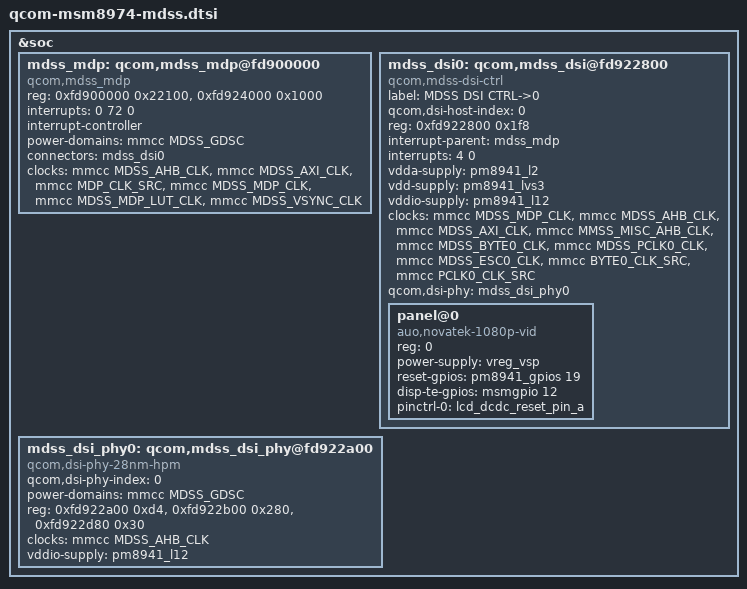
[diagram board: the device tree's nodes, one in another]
/* Copyright (c) 2015, The Linux Foundation. All rights reserved.
 *
 * This program is free software; you can redistribute it and/or modify
 * it under the terms of the GNU General Public License version 2 and
 * only version 2 as published by the Free Software Foundation.
 *
 * This program is distributed in the hope that it will be useful,
 * but WITHOUT ANY WARRANTY; without even the implied warranty of
 * MERCHANTABILITY or FITNESS FOR A PARTICULAR PURPOSE.  See the
 * GNU General Public License for more details.
 */

&soc {
//	gpu: qcom,adreno-3xx@fdb00000 {
//		compatible = "qcom,adreno-3xx";
//		#stream-id-cells = <16>;
//		reg = <0xfdb00000 0x10000>;
//		reg-names = "kgsl_3d0_reg_memory";
//		interrupts = <0 33 0>;
//		interrupt-names = "kgsl_3d0_irq";
//		clock-names =
//			"core_clk",
//			"iface_clk",
//			"mem_clk",
//			"mem_iface_clk",
//			"alt_mem_iface_clk",
//			"gfx3d_clk_src";
//		clocks =
//			<&gcc GCC_OXILI_GFX3D_CLK>,
//			<&gcc GCC_OXILI_AHB_CLK>,
//			<&gcc GCC_OXILI_GMEM_CLK>,
//			<&gcc GCC_BIMC_GFX_CLK>,
//			<&gcc GCC_BIMC_GPU_CLK>,
//			<&gcc GFX3D_CLK_SRC>;
//		power-domains = <&gcc OXILI_GDSC>;
//		qcom,chipid = <0x03030000>;
//		qcom,gpu-pwrlevels {
//			compatible = "qcom,gpu-pwrlevels";
//			qcom,gpu-pwrlevel@0 {
//				qcom,gpu-freq = <450000000>;
//			};
//			qcom,gpu-pwrlevel@1 {
//				qcom,gpu-freq = <27000000>;
//			};
//		};
//	};

	mdss_mdp: qcom,mdss_mdp@fd900000 {
		compatible = "qcom,mdss_mdp";
		reg = <0xfd900000 0x22100>,
			<0xfd924000 0x1000>;
		reg-names = "mdp_phys", "vbif_phys";
		interrupts = <0 72 0>;

		interrupt-controller;
		#interrupt-cells = <1>;

		power-domains = <&mmcc MDSS_GDSC>;

		connectors = <&mdss_dsi0>;
//		gpus = <&gpu>;

		clocks = <&mmcc MDSS_AHB_CLK>,
			<&mmcc MDSS_AXI_CLK>,
			<&mmcc MDP_CLK_SRC>,
			<&mmcc MDSS_MDP_CLK>,
			<&mmcc MDSS_MDP_LUT_CLK>,
			<&mmcc MDSS_VSYNC_CLK>;
		clock-names = "iface_clk", "bus_clk", "core_clk_src",
			"core_clk", "lut_clk", "vsync_clk";
	};

	mdss_dsi0: qcom,mdss_dsi@fd922800 {
		compatible = "qcom,mdss-dsi-ctrl";
		label = "MDSS DSI CTRL->0";
		qcom,dsi-host-index = <0>;
		#address-cells = <1>;
		#size-cells = <0>;
		reg = <0xfd922800 0x1f8>;
		reg-names = "dsi_ctrl";

		interrupt-parent = <&mdss_mdp>;
		interrupts = <4 0>;

		vdda-supply = <&pm8941_l2>;
		vdd-supply = <&pm8941_lvs3>;
		vddio-supply = <&pm8941_l12>;

		clocks = <&mmcc MDSS_MDP_CLK>,
			<&mmcc MDSS_AHB_CLK>,
			<&mmcc MDSS_AXI_CLK>,
			<&mmcc MMSS_MISC_AHB_CLK>,
			<&mmcc MDSS_BYTE0_CLK>,
			<&mmcc MDSS_PCLK0_CLK>,
			<&mmcc MDSS_ESC0_CLK>,
			<&mmcc BYTE0_CLK_SRC>,
			<&mmcc PCLK0_CLK_SRC>;
		clock-names = "mdp_core_clk", "iface_clk", "bus_clk",
			"core_mmss_clk", "byte_clk", "pixel_clk",
			"core_clk", "byte_clk_src", "pixel_clk_src";
		qcom,dsi-phy = <&mdss_dsi_phy0>;

		// XXX this should be in device specific dts file..
		panel@0 {
			reg = <0>;
			compatible = "auo,novatek-1080p-vid";
			power-supply = <&vreg_vsp>;
			reset-gpios = <&pm8941_gpios 19 GPIO_ACTIVE_HIGH>;
			disp-te-gpios = <&msmgpio 12 0>;
			pinctrl-names = "default";
			pinctrl-0 = <&lcd_dcdc_reset_pin_a>;
		};
	};

	mdss_dsi_phy0: qcom,mdss_dsi_phy@fd922a00 {
		compatible = "qcom,dsi-phy-28nm-hpm";
		qcom,dsi-phy-index = <0>;

		power-domains = <&mmcc MDSS_GDSC>;

		reg-names = "dsi_pll", "dsi_phy", "dsi_phy_regulator";
		reg = <0xfd922a00 0xd4>,
			<0xfd922b00 0x280>,
			<0xfd922d80 0x30>;

		clocks = <&mmcc MDSS_AHB_CLK>;
		clock-names = "iface_clk";

		vddio-supply = <&pm8941_l12>;
	};
};
